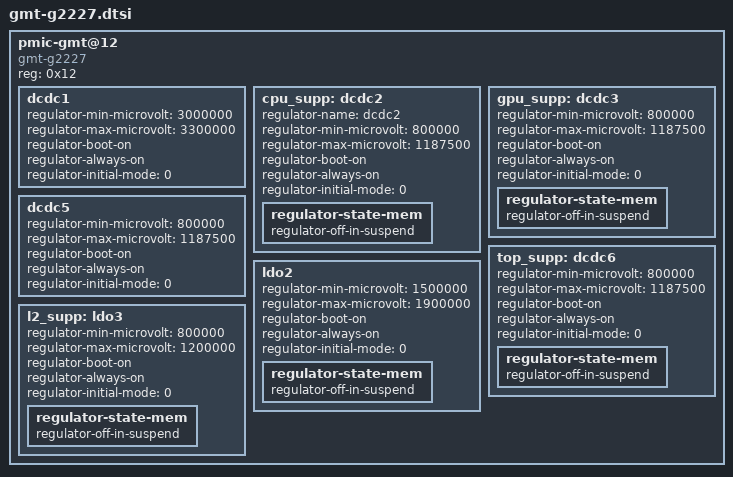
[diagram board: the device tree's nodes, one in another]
/* Please include this file in i2c node */
pmic-gmt@12 {
    compatible = "gmt-g2227";
    reg = <0x12>;
    status = "okay";

    dcdc1 {
        regulator-min-microvolt = <3000000>;
        regulator-max-microvolt = <3300000>;

        regulator-boot-on;
        regulator-always-on;
        regulator-initial-mode = <0>;
    };
    cpu_supp: dcdc2 {
        regulator-name = "dcdc2";
        regulator-min-microvolt = <800000>;
        regulator-max-microvolt = <1187500>;

        regulator-boot-on;
        regulator-always-on;
        regulator-initial-mode = <0>;
        regulator-state-mem {
            regulator-off-in-suspend;
        };
    };
    gpu_supp: dcdc3 {
        regulator-min-microvolt = <800000>;
        regulator-max-microvolt = <1187500>;

        regulator-boot-on;
        regulator-always-on;
        regulator-initial-mode = <0>;
        regulator-state-mem {
            regulator-off-in-suspend;
        };
    };
    dcdc5 {
        regulator-min-microvolt = <800000>;
        regulator-max-microvolt = <1187500>;

        regulator-boot-on;
        regulator-always-on;
        regulator-initial-mode = <0>;
    };
    top_supp: dcdc6 {
        regulator-min-microvolt = <800000>;
        regulator-max-microvolt = <1187500>;

        regulator-boot-on;
        regulator-always-on;
        regulator-initial-mode = <0>;
        regulator-state-mem {
            regulator-off-in-suspend;
        };
    };
    ldo2 {
        regulator-min-microvolt = <1500000>;
        regulator-max-microvolt = <1900000>;

        regulator-boot-on;
        regulator-always-on;
        regulator-initial-mode = <0>;
        regulator-state-mem {
            regulator-off-in-suspend;
        };
    };
    l2_supp: ldo3 {
        regulator-min-microvolt = <800000>;
        regulator-max-microvolt = <1200000>;

        regulator-boot-on;
        regulator-always-on;
        regulator-initial-mode = <0>;
        regulator-state-mem {
            regulator-off-in-suspend;
        };
    };
};    
